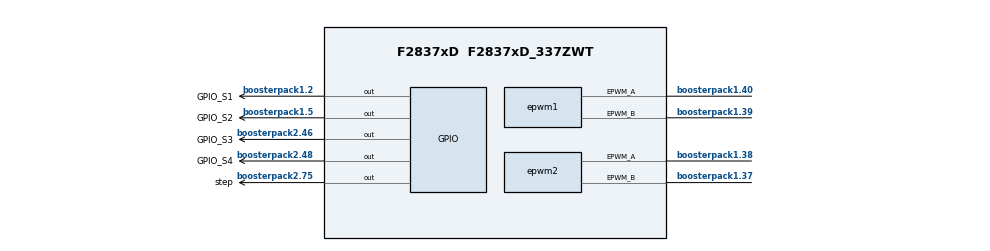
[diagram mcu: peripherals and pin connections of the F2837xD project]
/**
 * @cliArgs --board "/boards/LAUNCHXL_F28379D" --device "F2837xD" --part "F2837xD_337ZWT" --package "F2837xD_337ZWT" --context "CPU1" --product "C2000WARE@26.00.00.00"
 * @versions {"tool":"1.27.0+4565"}
 */

/**
 * Import the modules used in this configuration.
 */
const adc       = scripting.addModule("/driverlib/adc.js", {}, false);
const adc1      = adc.addInstance();
const cla       = scripting.addModule("/driverlib/cla.js", {}, false);
const cla1      = cla.addInstance();
const cputimer  = scripting.addModule("/driverlib/cputimer.js", {}, false);
const cputimer1 = cputimer.addInstance();
const dac       = scripting.addModule("/driverlib/dac.js", {}, false);
const dac1      = dac.addInstance();
const dac2      = dac.addInstance();
const epwm      = scripting.addModule("/driverlib/epwm.js", {}, false);
const epwm1     = epwm.addInstance();
const epwm2     = epwm.addInstance();
const gpio      = scripting.addModule("/driverlib/gpio.js", {}, false);
const gpio1     = gpio.addInstance();
const gpio2     = gpio.addInstance();
const gpio3     = gpio.addInstance();
const gpio4     = gpio.addInstance();
const gpio5     = gpio.addInstance();
const memcfg    = scripting.addModule("/driverlib/memcfg.js");
const CMD       = scripting.addModule("/utilities/cmd_tool/cmd_syscfg/source/CMD", {}, false);
const CMD1      = CMD.addInstance();

/**
 * Write custom configuration values to the imported modules.
 */
adc1.registerInterrupts      = ["1"];
adc1.$name                   = "ADC0";
adc1.adcClockPrescaler       = "ADC_CLK_DIV_4_0";
adc1.enabledSOCs             = ["ADC_SOC_NUMBER0","ADC_SOC_NUMBER1"];
adc1.soc0Name                = "SOC0_IO";
adc1.soc0Channel             = "ADC_CH_ADCIN3";
adc1.soc0Trigger             = "ADC_TRIGGER_CPU1_TINT0";
adc1.soc0SampleWindow        = 15;
adc1.soc1Name                = "SOC1_VO";
adc1.soc1Channel             = "ADC_CH_ADCIN2";
adc1.soc1Trigger             = "ADC_TRIGGER_CPU1_TINT0";
adc1.soc1SampleWindow        = 15;
adc1.interruptPulseMode      = "ADC_PULSE_END_OF_CONV";
adc1.enabledInts             = ["ADC_INT_NUMBER1"];
adc1.enableInterrupt1        = true;
adc1.interrupt1SOCSource     = "ADC_SOC_NUMBER1";
adc1.adcInt1.enableInterrupt = true;

cla1.$name             = "myCLA0";
cla1.enable_CLA_TASK_2 = false;
cla1.enable_CLA_TASK_4 = false;
cla1.enable_CLA_TASK_3 = false;
cla1.enable_CLA_TASK_5 = false;
cla1.enable_CLA_TASK_6 = false;
cla1.enable_CLA_TASK_7 = false;
cla1.enable_CLA_TASK_8 = false;
cla1.cpuint_CLA_TASK_2 = false;
cla1.cpuint_CLA_TASK_3 = false;
cla1.cpuint_CLA_TASK_5 = false;
cla1.cpuint_CLA_TASK_6 = false;
cla1.cpuint_CLA_TASK_7 = false;
cla1.cpuint_CLA_TASK_8 = false;
cla1.cpuint_CLA_TASK_4 = false;
cla1.cpuint_CLA_TASK_1 = false;

cputimer1.$name           = "myCPUTIMER0";
cputimer1.timerPeriod     = 999;
cputimer1.enableInterrupt = true;
cputimer1.startTimer      = true;

dac1.$name            = "DAC_IO";
dac1.dacBase          = "DACB_BASE";
dac1.enableOutput     = true;
dac1.referenceVoltage = "DAC_REF_ADC_VREFHI";

dac2.enableOutput     = true;
dac2.$name            = "DAC_VO";
dac2.referenceVoltage = "DAC_REF_ADC_VREFHI";

epwm1.$name                                                      = "EPWM_S1_S2";
epwm1.epwmTimebase_hsClockDiv                                    = "EPWM_HSCLOCK_DIVIDER_1";
epwm1.epwmDeadband_polarityFED                                   = "EPWM_DB_POLARITY_ACTIVE_LOW";
epwm1.epwmActionQualifier_EPWM_AQ_OUTPUT_A_ON_TIMEBASE_UP_CMPA   = "EPWM_AQ_OUTPUT_LOW";
epwm1.epwmTimebase_syncOutPulseMode                              = "EPWM_SYNC_OUT_PULSE_DISABLED";
epwm1.epwmCounterCompare_enableShadowLoadModeCMPA                = false;
epwm1.epwmTimebase_counterMode                                   = "EPWM_COUNTER_MODE_UP_DOWN";
epwm1.epwmActionQualifier_EPWM_AQ_OUTPUT_A_ON_TIMEBASE_DOWN_CMPA = "EPWM_AQ_OUTPUT_HIGH";
epwm1.epwmActionQualifier_EPWM_AQ_OUTPUT_B_ON_TIMEBASE_UP_CMPA   = "EPWM_AQ_OUTPUT_HIGH";
epwm1.epwmActionQualifier_EPWM_AQ_OUTPUT_B_ON_TIMEBASE_DOWN_CMPA = "EPWM_AQ_OUTPUT_LOW";
epwm1.epwmTimebase_period                                        = 2500;
epwm1.epwmDeadband_enableRED                                     = true;
epwm1.epwmDeadband_delayRED                                      = 100;
epwm1.epwmDeadband_delayFED                                      = 100;
epwm1.epwm.$assign                                               = "EPWM1";
epwm1.epwm.epwm_aPin.$assign                                     = "boosterpack1.40";
epwm1.epwm.epwm_bPin.$assign                                     = "boosterpack1.39";

epwm2.epwmTimebase_hsClockDiv                                    = "EPWM_HSCLOCK_DIVIDER_1";
epwm2.epwmDeadband_polarityFED                                   = "EPWM_DB_POLARITY_ACTIVE_LOW";
epwm2.$name                                                      = "EPWM_S3_S4";
epwm2.epwmActionQualifier_EPWM_AQ_OUTPUT_A_ON_TIMEBASE_UP_CMPA   = "EPWM_AQ_OUTPUT_LOW";
epwm2.epwmTimebase_syncOutPulseMode                              = "EPWM_SYNC_OUT_PULSE_DISABLED";
epwm2.epwmCounterCompare_enableShadowLoadModeCMPA                = false;
epwm2.epwmTimebase_counterMode                                   = "EPWM_COUNTER_MODE_UP_DOWN";
epwm2.epwmActionQualifier_EPWM_AQ_OUTPUT_A_ON_TIMEBASE_DOWN_CMPA = "EPWM_AQ_OUTPUT_HIGH";
epwm2.epwmActionQualifier_EPWM_AQ_OUTPUT_B_ON_TIMEBASE_UP_CMPA   = "EPWM_AQ_OUTPUT_HIGH";
epwm2.epwmActionQualifier_EPWM_AQ_OUTPUT_B_ON_TIMEBASE_DOWN_CMPA = "EPWM_AQ_OUTPUT_LOW";
epwm2.epwmTimebase_period                                        = 2500;
epwm2.epwmDeadband_enableRED                                     = true;
epwm2.epwmDeadband_enableFED                                     = true;
epwm2.epwmDeadband_delayRED                                      = 100;
epwm2.epwmDeadband_delayFED                                      = 100;
epwm2.epwm.$assign                                               = "EPWM2";
epwm2.epwm.epwm_aPin.$assign                                     = "boosterpack1.38";
epwm2.epwm.epwm_bPin.$assign                                     = "boosterpack1.37";

gpio1.$name           = "GPIO_S1";
gpio1.padConfig       = "PULLUP";
gpio1.gpioPin.$assign = "boosterpack1.2";

gpio2.$name           = "GPIO_S2";
gpio2.padConfig       = "PULLUP";
gpio2.gpioPin.$assign = "boosterpack1.5";

gpio3.$name           = "GPIO_S3";
gpio3.padConfig       = "PULLUP";
gpio3.gpioPin.$assign = "boosterpack2.46";

gpio4.$name           = "GPIO_S4";
gpio4.padConfig       = "PULLUP";
gpio4.gpioPin.$assign = "boosterpack2.48";

gpio5.$name           = "step";
gpio5.direction       = "GPIO_DIR_MODE_OUT";
gpio5.gpioPin.$assign = "boosterpack2.75";

memcfg.init_MEMCFG_SECT_MSGCPUTOCLA1 = true;
memcfg.init_MEMCFG_SECT_MSGCLA1TOCPU = true;
memcfg.config_MEMCFG_SECT_LS1        = "CLA_data";
memcfg.config_MEMCFG_SECT_LS4        = "CLA_prog";
memcfg.config_MEMCFG_SECT_LS5        = "CLA_prog";

CMD1.$name                         = "CMD0";
CMD1.sectionMemory_cpuToCla1MsgRAM = ["CPUTOCLA_MSGRAM"];
CMD1.sectionMemory_cla1ToCpuMsgRAM = ["CLATOCPU_MSGRAM"];
CMD1.sectionMemory_claScratchpad   = ["RAMLS1"];
CMD1.sectionMemory_claConst        = ["RAMLS1"];
CMD1.sectionMemory_cla1Prog        = ["RAMLS5"];
